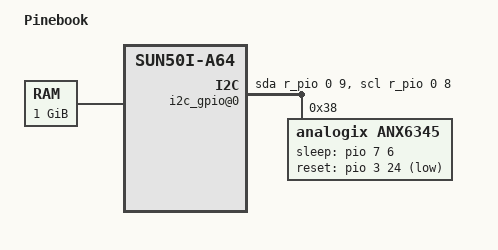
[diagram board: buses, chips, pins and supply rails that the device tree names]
/*
 * Copyright (c) 2016 ARM Ltd.
 *
 * This file is dual-licensed: you can use it either under the terms
 * of the GPL or the X11 license, at your option. Note that this dual
 * licensing only applies to this file, and not this project as a
 * whole.
 *
 *  a) This library is free software; you can redistribute it and/or
 *     modify it under the terms of the GNU General Public License as
 *     published by the Free Software Foundation; either version 2 of the
 *     License, or (at your option) any later version.
 *
 *     This library is distributed in the hope that it will be useful,
 *     but WITHOUT ANY WARRANTY; without even the implied warranty of
 *     MERCHANTABILITY or FITNESS FOR A PARTICULAR PURPOSE.  See the
 *     GNU General Public License for more details.
 *
 * Or, alternatively,
 *
 *  b) Permission is hereby granted, free of charge, to any person
 *     obtaining a copy of this software and associated documentation
 *     files (the "Software"), to deal in the Software without
 *     restriction, including without limitation the rights to use,
 *     copy, modify, merge, publish, distribute, sublicense, and/or
 *     sell copies of the Software, and to permit persons to whom the
 *     Software is furnished to do so, subject to the following
 *     conditions:
 *
 *     The above copyright notice and this permission notice shall be
 *     included in all copies or substantial portions of the Software.
 *
 *     THE SOFTWARE IS PROVIDED "AS IS", WITHOUT WARRANTY OF ANY KIND,
 *     EXPRESS OR IMPLIED, INCLUDING BUT NOT LIMITED TO THE WARRANTIES
 *     OF MERCHANTABILITY, FITNESS FOR A PARTICULAR PURPOSE AND
 *     NONINFRINGEMENT. IN NO EVENT SHALL THE AUTHORS OR COPYRIGHT
 *     HOLDERS BE LIABLE FOR ANY CLAIM, DAMAGES OR OTHER LIABILITY,
 *     WHETHER IN AN ACTION OF CONTRACT, TORT OR OTHERWISE, ARISING
 *     FROM, OUT OF OR IN CONNECTION WITH THE SOFTWARE OR THE USE OR
 *     OTHER DEALINGS IN THE SOFTWARE.
 */

/dts-v1/;

#include "sun50i-a64-pine64.dts"

/ {
	model = "Pinebook";
	compatible = "pine64,pinebook", "allwinner,sun50i-a64";

	aliases {
		serial0 = &uart0;
		i2c0 = "/i2c_gpio@0";
	};

	chosen {
		stdout-path = "serial0:115200n8";
	};

	memory {
		reg = <0x40000000 0x40000000>;
	};

	soc {
		/*pio {
			i2c_lcd_pins: i2c_lcd_pins {
				pins = "PL9", "PL8";
				function = "gpio_out";
				drive-strength = <30>;
				bias-pull-up;
			};
		};*/

		i2c_gpio@0 {
			compatible = "i2c-gpio";
			/*pinctrl-names = "default";
			pinctrl-0 = <&i2c_lcd_pins>;*/
			gpios = <&r_pio 0 9 GPIO_ACTIVE_HIGH>, /* sda - PL9 */ 
				<&r_pio 0 8 GPIO_ACTIVE_HIGH>; /* scl - PL8 */
			i2c-gpio,sda-open-drain;
			i2c-gpio,scl-open-drain;
			i2c-gpio,delay-us = <2>;	/* ~100 kHz */
			#address-cells = <1>;
			#size-cells = <0>;
			status = "okay";

			anx6345: edp-bridge@38 {
				compatible = "analogix,anx6345";
				reg = <0x38>;
				sleep-gpios = <&pio 7 6 GPIO_ACTIVE_HIGH>; /* PH6 */
				reset-gpios = <&pio 3 24 GPIO_ACTIVE_LOW>; /* PD24 */
				status = "okay";

				/*
				ports {
					port@0 {
						bridge_out: endpoint {
							remote-endpoint = <&panel_in>;
						};
					};

					port@1 {
						bridge_in: endpoint {
							remote-endpoint = <&rgb_out>;
						};
					};
				};
				*/
			};
		};
	};
};
